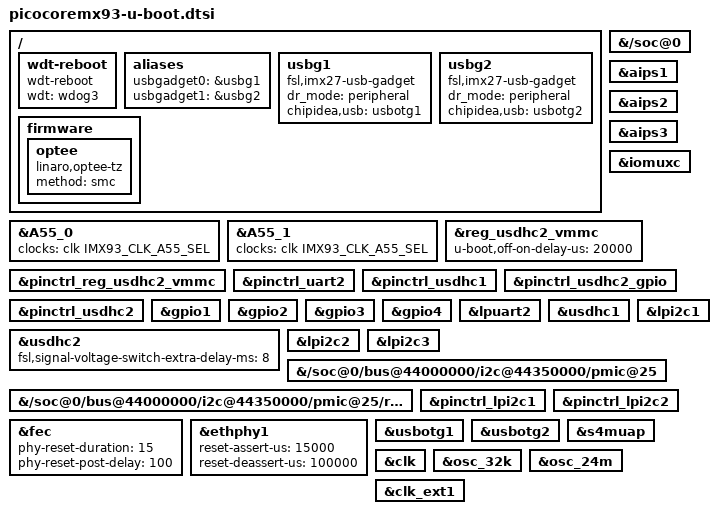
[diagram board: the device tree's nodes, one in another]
/*
* Copyright 2024 F&S Elektronik Systeme GmbH
*
* This program is free software; you can redistribute it and/or modify
* it under the terms of the GNU General Public License version 2 as
* published by the Free Software Foundation.
*
* This program is distributed in the hope that it will be useful,
* but WITHOUT ANY WARRANTY; without even the implied warranty of
* MERCHANTABILITY or FITNESS FOR A PARTICULAR PURPOSE.  See the
* GNU General Public License for more details.
*/

/ {
	wdt-reboot {
		compatible = "wdt-reboot";
		wdt = <&wdog3>;
		bootph-pre-ram;
		bootph-some-ram;
	};

	aliases {
		usbgadget0 = &usbg1;
		usbgadget1 = &usbg2;
	};

	usbg1: usbg1 {
		compatible = "fsl,imx27-usb-gadget";
		dr_mode = "peripheral";
		chipidea,usb = <&usbotg1>;
		status = "okay";
	};

	usbg2: usbg2 {
		compatible = "fsl,imx27-usb-gadget";
		dr_mode = "peripheral";
		chipidea,usb = <&usbotg2>;
		status = "okay";
	};

	firmware {
		optee {
			compatible = "linaro,optee-tz";
			method = "smc";
		};
	};
};

&A55_0 {
	clocks = <&clk IMX93_CLK_A55_SEL>;
};

&A55_1 {
	clocks = <&clk IMX93_CLK_A55_SEL>;
};

&{/soc@0} {
	bootph-all;
	bootph-pre-ram;
};

&aips1 {
	bootph-pre-ram;
	bootph-all;
};

&aips2 {
	bootph-pre-ram;
	bootph-some-ram;
};

&aips3 {
	bootph-pre-ram;
	bootph-some-ram;
};

&iomuxc {
	bootph-pre-ram;
	bootph-some-ram;
};

&reg_usdhc2_vmmc {
	u-boot,off-on-delay-us = <20000>;
	bootph-pre-ram;
};

&pinctrl_reg_usdhc2_vmmc {
	bootph-pre-ram;
};

&pinctrl_uart2 {
	bootph-pre-ram;
	bootph-some-ram;
};

&pinctrl_usdhc1 {
	bootph-pre-ram;
};

&pinctrl_usdhc2_gpio {
	bootph-pre-ram;
};

&pinctrl_usdhc2 {
	bootph-pre-ram;
};

&gpio1 {
	bootph-pre-ram;
	bootph-some-ram;
};

&gpio2 {
	bootph-pre-ram;
	bootph-some-ram;
};

&gpio3 {
	bootph-pre-ram;
	bootph-some-ram;
};

&gpio4 {
	bootph-pre-ram;
	bootph-some-ram;
};

&lpuart2 {
	bootph-pre-ram;
	bootph-some-ram;
};

&usdhc1 {
	bootph-pre-ram;
};

&usdhc2 {
	bootph-pre-ram;
	fsl,signal-voltage-switch-extra-delay-ms = <8>;
};

&lpi2c1 {
	bootph-pre-ram;
};

&lpi2c2 {
	bootph-pre-ram;
};

&lpi2c3 {
	bootph-pre-ram;
};

&{/soc@0/bus@44000000/i2c@44350000/pmic@25} {
	bootph-pre-ram;
};

&{/soc@0/bus@44000000/i2c@44350000/pmic@25/regulators} {
	bootph-pre-ram;
};

&pinctrl_lpi2c1 {
	bootph-pre-ram;
};

&pinctrl_lpi2c2 {
	bootph-pre-ram;
};

&fec {
	phy-reset-duration = <15>;
	phy-reset-post-delay = <100>;
};

&ethphy1 {
	reset-assert-us = <15000>;
	reset-deassert-us = <100000>;
};

&usbotg1 {
	status = "okay";
};

&usbotg2 {
	status = "okay";
};

&s4muap {
	bootph-pre-ram;
	bootph-some-ram;
	status = "okay";
};

&clk {
	bootph-all;
	bootph-pre-ram;
	/delete-property/ assigned-clocks;
	/delete-property/ assigned-clock-rates;
	/delete-property/ assigned-clock-parents;
};

&osc_32k {
	bootph-all;
	bootph-pre-ram;
};

&osc_24m {
	bootph-all;
	bootph-pre-ram;
};

&clk_ext1 {
	bootph-all;
	bootph-pre-ram;
};

